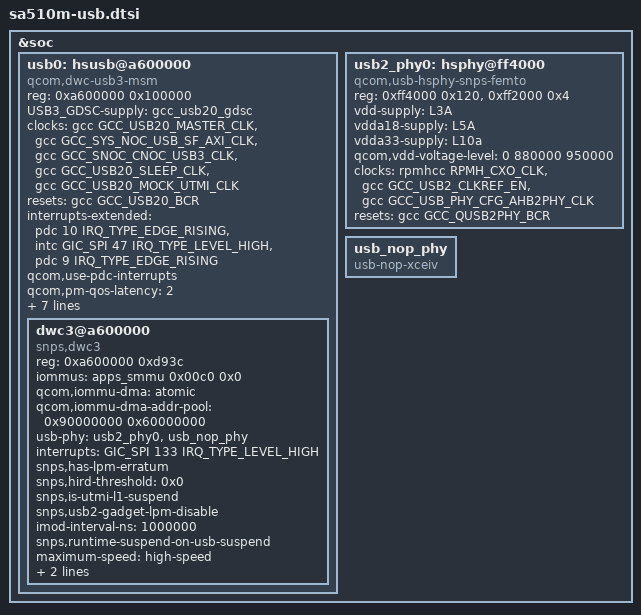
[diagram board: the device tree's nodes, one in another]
// SPDX-License-Identifier: BSD-3-Clause
/*
 * Copyright (c) Qualcomm Technologies, Inc. and/or its subsidiaries.
 */

#include <dt-bindings/clock/qcom,gcc-sdxbaagha.h>

&soc {
	usb0: hsusb@a600000 {
		compatible = "qcom,dwc-usb3-msm";
		reg = <0xa600000 0x100000>;
		reg-names = "core_base";

		#address-cells = <1>;
		#size-cells = <1>;
		ranges;

		USB3_GDSC-supply = <&gcc_usb20_gdsc>;

		clocks = <&gcc GCC_USB20_MASTER_CLK>,
			<&gcc GCC_SYS_NOC_USB_SF_AXI_CLK>,
			<&gcc GCC_SNOC_CNOC_USB3_CLK>,
			<&gcc GCC_USB20_SLEEP_CLK>,
			<&gcc GCC_USB20_MOCK_UTMI_CLK>;

		clock-names = "core_clk", "iface_clk", "bus_aggr_clk",
				"sleep_clk", "utmi_clk";

		resets = <&gcc GCC_USB20_BCR>;
		reset-names = "core_reset";
		interrupts-extended = <&pdc 10 IRQ_TYPE_EDGE_RISING>,
					<&intc GIC_SPI 47 IRQ_TYPE_LEVEL_HIGH>,
					<&pdc 9 IRQ_TYPE_EDGE_RISING>;

		interrupt-names = "dp_hs_phy_irq", "pwr_event_irq", "dm_hs_phy_irq";
		qcom,use-pdc-interrupts;
		qcom,pm-qos-latency = <2>;
		qcom,core-clk-rate = <60000000>;
		qcom,sleep-clk-bcr;
		qcom,default-bus-vote = <3>; /* use low svs bus voting */

		qcom,num-gsi-evt-buffs = <0x3>;
		qcom,gsi-reg-offset =
				<0x0fc /* GSI_GENERAL_CFG */
				0x110 /* GSI_DBL_ADDR_L */
				0x120 /* GSI_DBL_ADDR_H */
				0x130 /* GSI_RING_BASE_ADDR_L */
				0x144 /* GSI_RING_BASE_ADDR_H */
				0x1a4>; /* GSI_IF_STS */

		extcon = <&pmx35_vbus_detect>, <&eud>;

		dwc3@a600000 {
			compatible = "snps,dwc3";
			reg = <0xa600000 0xd93c>;
			iommus = <&apps_smmu 0x00c0 0x0>;
			qcom,iommu-dma = "atomic";
			qcom,iommu-dma-addr-pool = <0x90000000 0x60000000>;
			usb-phy = <&usb2_phy0>,<&usb_nop_phy>;
			interrupts = <GIC_SPI 133 IRQ_TYPE_LEVEL_HIGH>;
			snps,has-lpm-erratum;
			snps,hird-threshold = /bits/ 8 <0x0>;
			snps,is-utmi-l1-suspend;
			snps,usb2-gadget-lpm-disable;
			imod-interval-ns = <1000000>;
			snps,runtime-suspend-on-usb-suspend;
			/* tx-fifo-resize not required since RAM_DEPTH is 0*/
			maximum-speed = "high-speed";
			dr_mode = "otg";
			usb-role-switch;
		};
	};

	/* USB port related High Speed PHY */
	usb2_phy0: hsphy@ff4000 {
		compatible = "qcom,usb-hsphy-snps-femto";
		reg = <0xff4000 0x120>,
			<0xff2000 0x4>;
		reg-names = "hsusb_phy_base",
				"eud_enable_reg";


		vdd-supply = <&L3A>;
		vdda18-supply = <&L5A>;
		vdda33-supply = <&L10a>;
		qcom,vdd-voltage-level = <0 880000 950000>;

		clocks = <&rpmhcc RPMH_CXO_CLK>,
			<&gcc GCC_USB2_CLKREF_EN>,
			<&gcc GCC_USB_PHY_CFG_AHB2PHY_CLK>;
		clock-names = "ref_clk_src", "ref_clk", "cfg_ahb_clk";

		resets = <&gcc GCC_QUSB2PHY_BCR>;
		reset-names = "phy_reset";
	};

	usb_nop_phy: usb_nop_phy {
		compatible = "usb-nop-xceiv";
	};
};
